# cmem7 register map
File version: 1.0
ARM 32-bit Cortex-M3 Microcontroller based device, CPU clock up to 80MHz, etc.
Registers are 32-bit, read-write, reset 0x0 unless marked. A register's access mark holds for its fields unless they carry their own. Offsets are from the block's base; lines under a group give offsets from that group; [hi:lo] are bit positions; {n}, {i} and the like mark numbered series; 'fields as' and 'values as' point back to an identical list; <NAME> marks a mode.

## Memory map
0x40800000 NOR_FLASH size 0x18
0x41000000 TIMER0 size 0x1C
0x41000020 TIMER1 size 0x1C
0x41000040 TIMER2 size 0x1C
0x41000060 TIMER3 size 0x1C
0x41001000 WDG size 0x18 — watchdog
0x41002000 GPIO size 0x78
0x41003000 I2C0 size 0x74
0x41004000 SPI0 size 0x2C
0x41005000 UART0 size 0x30 — asynchronous serial controller 0
0x41006000 ADC size 0x78
0x41007000 PDLOCK size 0x4 — PLL DLL LOCK
0x41007004 RTC size 0x10
0x41007010 GLOBAL_CTRL size 0x438
0x41007400 SOFT_RESET size 0x4 — SUB SOFT RESET
0x41007C00 PDPROT size 0x4 — PLL DLL PROTECT
0x41008000 EFUSE size 0x44
0x41009000 CAN0 size 0x1B4
0x4100A000 I2C1 size 0x74
0x4100B000 SPI1 size 0x2C
0x4100C000 UART1 size 0x30 — asynchronous serial controller 1
0x4100D000 CAN1 size 0x1B4
0x4100E000 UART2 size 0x30 — asynchronous serial controller 2
0x41200000 ETH size 0x1278
0x41300000 USB size 0x11000
0x41400000 DDRC size 0xB5 — DDR_CFG
0x41500000 DMA size 0x400
0x41600000 AES size 0x14
0x41700000 CFG_CTRL size 0xB8

## Interrupts
0 ETH_INT (ETH)
1 USB_INT (USB)
2 DMA_INT (DMA)
3 CAN0_INT (CAN0)
4 CAN1_INT (CAN1)
{n+5} FP{n}_INT (GLOBAL_CTRL) (n=0..15)
21 UART0_INT (UART0)
22 UART1_INT (UART1)
23 ADC_INT (ADC)
24 GPIO_INT (GPIO)
25 SPI1_INT (SPI1)
26 I2C1_INT (I2C1)
27 SPI0_INT (SPI0)
28 I2C0_INT (I2C0)
29 RTC_1S_INT (RTC)
30 RTC_1MS_INT (RTC)
31 WDG_INT (WDG)
32 TIMER_INT (TIMER0)
33 DDRC_SW_PROC (DDRC)
34 ETH_PMT_INT (ETH)
35 PAD_INT (GLOBAL_CTRL)
36 DDRC_LANE_SYNC (DDRC)
37 UART2_INT (UART2)

## UART0 — asynchronous serial controller 0
Base 0x41005000
Same registers: UART1 0x4100C000, UART2 0x4100E000
0x00 BAUDRATE 16-bit reset 0x8
0x04 TX_BUF 16-bit (reset mask 0x1FF) — transmit buffer Register
0x08 RX_BUF 16-bit ro (reset mask 0x3FF) — receive buffer Register
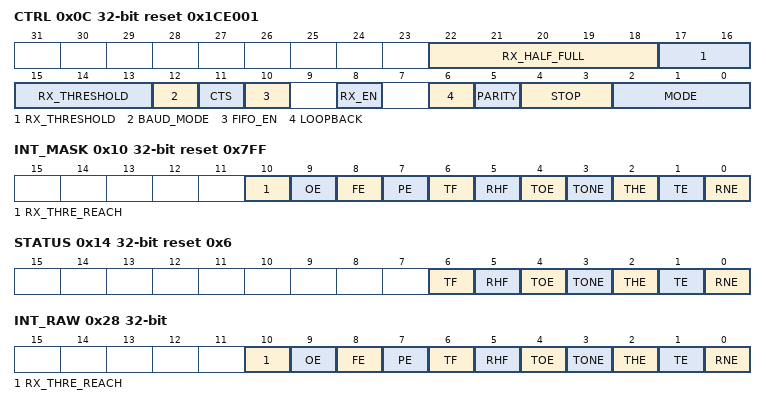
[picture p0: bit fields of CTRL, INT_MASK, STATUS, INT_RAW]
0x0C CTRL reset 0x1CE001 — control Register
  [22:18] RX_HALF_FULL — receive fifi half full level
  [17:13] RX_THRESHOLD — receive threshold
  [12] BAUD_MODE — baudrate generation mode
    0=BAUD_MODE_DECREMENT (baud counter decrements, ticks when it reaches 1); 1=BAUD_MODE_INCREMENT (baud counter increments, ticks when there is a carry)
  [11] CTS — Clear to send, enable signal to send
    0=IGNORED (CTS is ignored); 1=ENABLE (CTS is enabled)
  [10] FIFO_EN — FIFO enable bit
  [8] RX_EN — receive enable bit
  [6] LOOPBACK — loopback mode enable bit
  [5] PARITY — parity selection
    0=PARITY_EVEN (even parity); 1=PARITY_ODD (odd parity)
  [4:3] STOP — number of stop bits selection
    0=STOP_HALF (0.5 stop bit); 1=STOP_ONE (1 stop bit); 2=STOP_ONE_AND_HALF (1.5 stop bit); 3=STOP_TWO (2 stop bits)
  [2:0] MODE — asc mode control
    1=MODE_8BIT (8-bit data in buffer); 3=MODE_7BIT_PARITY (7-bit data and parity in buffer); 4=MODE_9BIT (9-bit data in buffer); 5=MODE_8BIT_WAKEUP (8-bit data and a wakeup bit in buffer); 7=MODE_8BIT_PARITY (8-bit data and parity in buffer)
0x10 INT_MASK reset 0x7FF — interrupt mask register
  [10] RX_THRE_REACH — Receive threshold reach interrupt
  [9] OE — overrun error interrupt
  [8] FE — frame error interrupt
  [7] PE — parity error interrupt
  [6] TF — transmitter FIFO full interrupt
  [5] RHF — receiver FIFO is half full interrupt
  [4] TOE — timeout when the receiver FIFO is empty interrupt
  [3] TONE — timeout when the receiver FIFO is not empty interrupt
  [2] THE — Transmitter FIFO at least half empty flag
  [1] TE — Transmitter FIFO empty interrupt
  [0] RNE — Receive FIFO not empty interrupt
0x14 STATUS reset 0x6
  [6] TF — transmitter FIFO is full
  [5] RHF — receiver FIFO is half full
  [4] TOE — time out when the receiver FIFO is empty
  [3] TONE — timeout when the receiver FIFO is not empty
  [2] THE — Transmitter FIFO at least half empty flag
  [1] TE — Transmitter FIFO empty
  [0] RNE — receiver FIFO not empty
0x18 TIMEOUT 8-bit
0x1C TX_RESET — transmit reset Register
  [0] EN — enable
0x20 RX_RESET — receive reset Register
  [0] EN — enable
0x24 RUN — uart enable register
  [0] EN — enable
0x28 INT_RAW — raw interrupt before mask register
  fields as INT_MASK
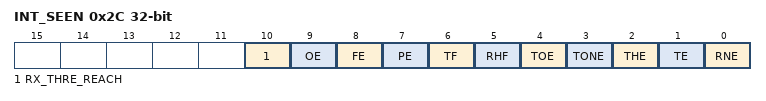
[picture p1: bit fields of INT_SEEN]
0x2C INT_SEEN — interrupt after mask register
  fields as INT_MASK

## Notices in the file
Copyright (C) 2012 ARM Limited. All rights reserved.
